# LPC18xx register map
File version: 18
Registers are 32-bit, read-write, reset 0x0 unless marked. A register's access mark holds for its fields unless they carry their own. Offsets are from the block's base; [hi:lo] are bit positions; 'fields as' and 'values as' point back to an identical list.

## RTC — Product name title=UM10430 Chapter title=LPC18xx Real-Time Clock (RTC) Modification date=1/20/2011 Major revision=0 Minor revision=7
Base 0x40046000
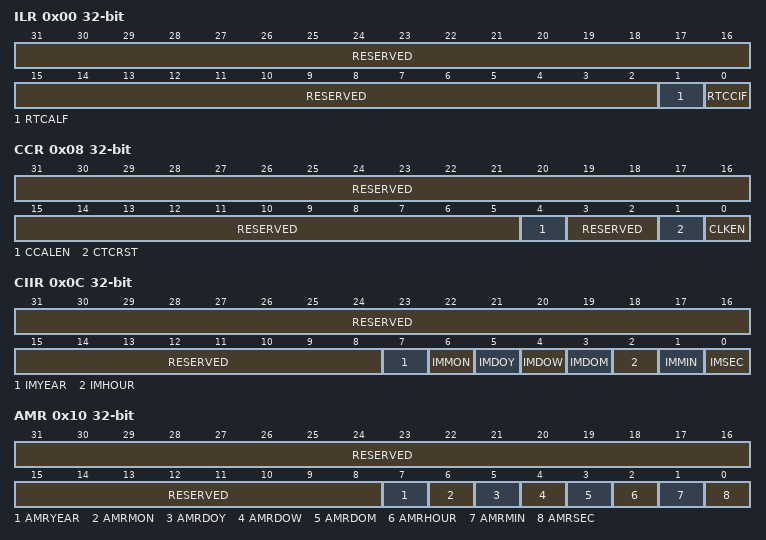
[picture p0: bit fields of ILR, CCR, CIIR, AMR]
0x00 ILR wo — Interrupt Location Register
  [31:2] RESERVED — Reserved, user software should not write ones to reserved bits. The value read from a reserved bit is not defined.
  [1] RTCALF — When one, the alarm registers generated an interrupt. Writing a one to this bit location clears the alarm interrupt.
  [0] RTCCIF — When one, the Counter Increment Interrupt block generated an interrupt. Writing a one to this bit location clears the counter increment interrupt.
0x08 CCR — Clock Control Register
  [31:5] RESERVED — Reserved, user software should not write ones to reserved bits. The value read from a reserved bit is not defined.
  [4] CCALEN — Calibration counter enable.
    0=ENABLED (The calibration counter is enabled and counting, using the 1 Hz clock. When the calibration counter is equal to the value of the CALIBRATION register, the counter resets and repeats counting up to the value of the CALIBRATION register. See Section 29.6.6.2 and Section 29.7.1.); 1=DISABLED (The calibration counter is disabled and reset to zero.)
  [3:2] RESERVED — Internal test mode controls. These bits must be 0 for normal RTC operation.
  [1] CTCRST — CTC Reset.
    0=NO_EFFECT_; 1=Reset value (When one, the elements in the internal oscillator divider are reset, and remain reset until CCR[1] is changed to zero. This is the divider that generates the 1 Hz clock from the 32.768 kHz crystal. The state of the divider is not visible to software.)
  [0] CLKEN — Clock Enable.
    0=DISABLED (The time counters are disabled so that they may be initialized.); 1=ENABLED (The time counters are enabled.)
0x0C CIIR — Counter Increment Interrupt Register
  [31:8] RESERVED — Reserved, user software should not write ones to reserved bits. The value read from a reserved bit is not defined.
  [7] IMYEAR — When 1, an increment of the Year value generates an interrupt.
  [6] IMMON — When 1, an increment of the Month value generates an interrupt.
  [5] IMDOY — When 1, an increment of the Day of Year value generates an interrupt.
  [4] IMDOW — When 1, an increment of the Day of Week value generates an interrupt.
  [3] IMDOM — When 1, an increment of the Day of Month value generates an interrupt.
  [2] IMHOUR — When 1, an increment of the Hour value generates an interrupt.
  [1] IMMIN — When 1, an increment of the Minute value generates an interrupt.
  [0] IMSEC — When 1, an increment of the Second value generates an interrupt.
0x10 AMR — Alarm Mask Register
  [31:8] RESERVED — Reserved, user software should not write ones to reserved bits. The value read from a reserved bit is not defined.
  [7] AMRYEAR — When 1, the Year value is not compared for the alarm.
  [6] AMRMON — When 1, the Month value is not compared for the alarm.
  [5] AMRDOY — When 1, the Day of Year value is not compared for the alarm.
  [4] AMRDOW — When 1, the Day of Week value is not compared for the alarm.
  [3] AMRDOM — When 1, the Day of Month value is not compared for the alarm.
  [2] AMRHOUR — When 1, the Hour value is not compared for the alarm.
  [1] AMRMIN — When 1, the Minutes value is not compared for the alarm.
  [0] AMRSEC — When 1, the Second value is not compared for the alarm.
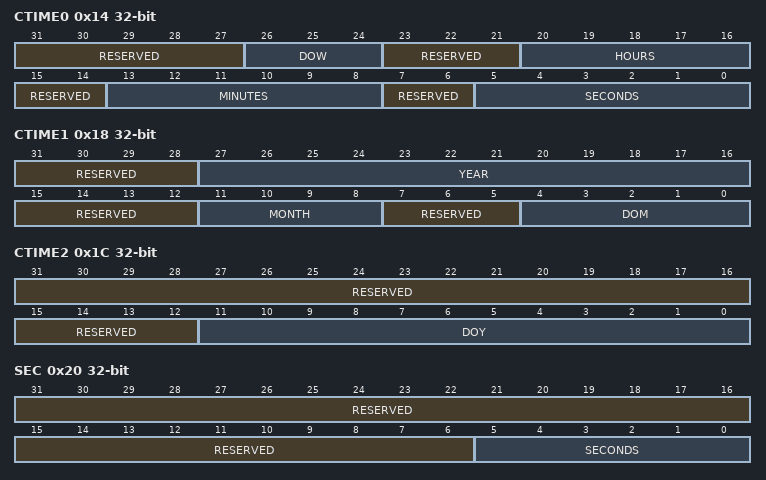
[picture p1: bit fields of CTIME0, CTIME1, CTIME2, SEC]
0x14 CTIME0 ro — Consolidated Time Register 0
  [31:27] RESERVED — Reserved, user software should not write ones to reserved bits. The value read from a reserved bit is not defined.
  [26:24] DOW — Day of week value in the range of 0 to 6
  [23:21] RESERVED — Reserved, user software should not write ones to reserved bits. The value read from a reserved bit is not defined.
  [20:16] HOURS — Hours value in the range of 0 to 23
  [15:14] RESERVED — Reserved, user software should not write ones to reserved bits. The value read from a reserved bit is not defined.
  [13:8] MINUTES — Minutes value in the range of 0 to 59
  [7:6] RESERVED — Reserved, user software should not write ones to reserved bits. The value read from a reserved bit is not defined.
  [5:0] SECONDS — Seconds value in the range of 0 to 59
0x18 CTIME1 ro — Consolidated Time Register 1
  [31:28] RESERVED — Reserved, user software should not write ones to reserved bits. The value read from a reserved bit is not defined.
  [27:16] YEAR — Year value in the range of 0 to 4095.
  [15:12] RESERVED — Reserved, user software should not write ones to reserved bits. The value read from a reserved bit is not defined.
  [11:8] MONTH — Month value in the range of 1 to 12.
  [7:5] RESERVED — Reserved, user software should not write ones to reserved bits. The value read from a reserved bit is not defined.
  [4:0] DOM — Day of month value in the range of 1 to 28, 29, 30, or 31 (depending on the month and whether it is a leap year).
0x1C CTIME2 ro — Consolidated Time Register 2
  [31:12] RESERVED — Reserved, user software should not write ones to reserved bits. The value read from a reserved bit is not defined.
  [11:0] DOY — Day of year value in the range of 1 to 365 (366 for leap years).
0x20 SEC — Seconds Register
  [31:6] RESERVED — Reserved, user software should not write ones to reserved bits. The value read from a reserved bit is not defined.
  [5:0] SECONDS — Seconds value in the range of 0 to 59
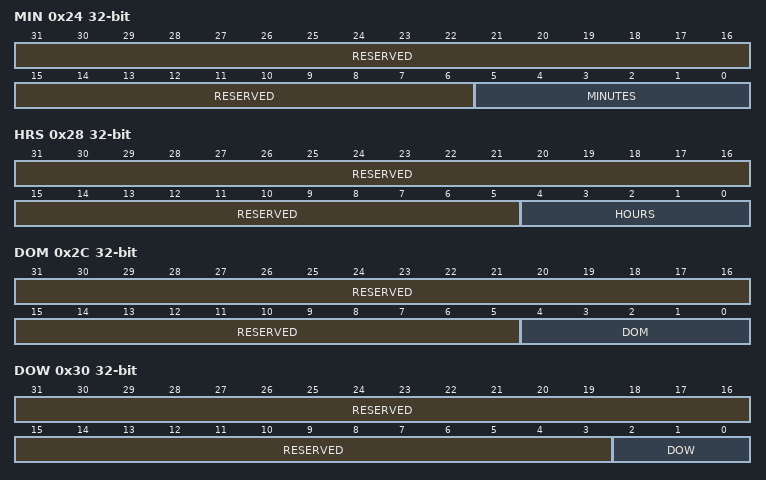
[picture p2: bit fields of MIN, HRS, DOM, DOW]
0x24 MIN — Minutes Register
  [31:6] RESERVED — Reserved, user software should not write ones to reserved bits. The value read from a reserved bit is not defined.
  [5:0] MINUTES — Minutes value in the range of 0 to 59
0x28 HRS — Hours Register
  [31:5] RESERVED — Reserved, user software should not write ones to reserved bits. The value read from a reserved bit is not defined.
  [4:0] HOURS — Hours value in the range of 0 to 23
0x2C DOM — Day of Month Register
  [31:5] RESERVED — Reserved, user software should not write ones to reserved bits. The value read from a reserved bit is not defined.
  [4:0] DOM — Day of month value in the range of 1 to 28, 29, 30, or 31 (depending on the month and whether it is a leap year).
0x30 DOW — Day of Week Register
  [31:3] RESERVED — Reserved, user software should not write ones to reserved bits. The value read from a reserved bit is not defined.
  [2:0] DOW — Day of week value in the range of 0 to 6.
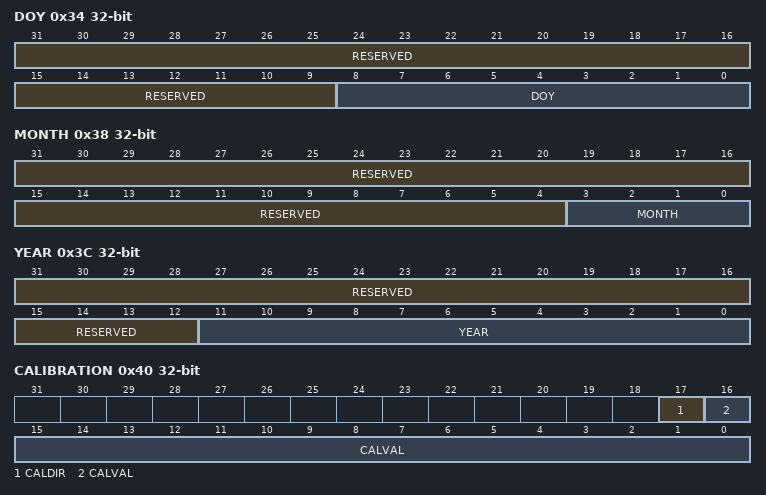
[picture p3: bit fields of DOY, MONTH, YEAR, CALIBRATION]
0x34 DOY — Day of Year Register
  [31:9] RESERVED — Reserved, user software should not write ones to reserved bits. The value read from a reserved bit is not defined.
  [8:0] DOY — Day of year value in the range of 1 to 365 (366 for leap years).
0x38 MONTH — Months Register
  [31:4] RESERVED — Reserved, user software should not write ones to reserved bits. The value read from a reserved bit is not defined.
  [3:0] MONTH — Month value in the range of 1 to 12.
0x3C YEAR — Years Register
  [31:12] RESERVED — Reserved, user software should not write ones to reserved bits. The value read from a reserved bit is not defined.
  [11:0] YEAR — Year value in the range of 0 to 4095.
0x40 CALIBRATION — Calibration Value Register
  [17] CALDIR — Calibration direction
    0=FORWARD_CALIBRATION_ (Forward calibration. When CALVAL is equal to the calibration counter, the RTC timers will jump by 2 seconds.); 1=BACKWARD_CALIBRATION (Backward calibration. When CALVAL is equal to the calibration counter, the RTC timers will stop incrementing for 1 second.)
  [16:0] CALVAL — If enabled, the calibration counter counts up to this value. The maximum value is 131 072 corresponding to about 36.4 hours. Calibration is disabled if CALVAL = 0.
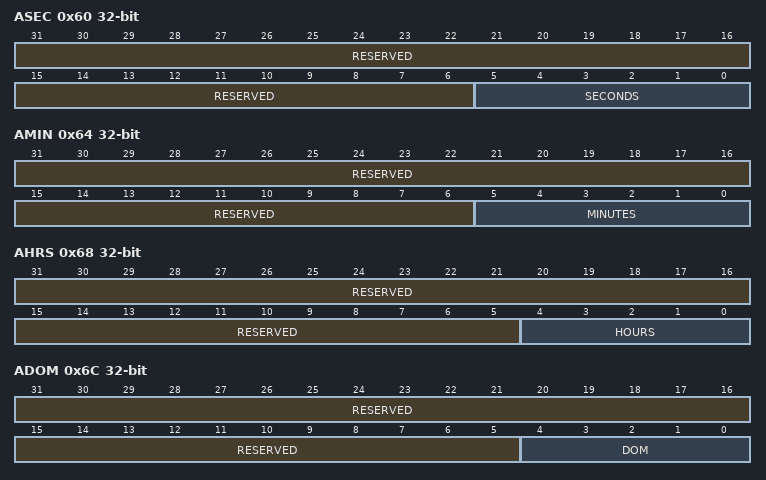
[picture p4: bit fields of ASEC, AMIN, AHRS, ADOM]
0x60 ASEC — Alarm value for Seconds
  fields as SEC
0x64 AMIN — Alarm value for Minutes
  fields as MIN
0x68 AHRS — Alarm value for Hours
  fields as HRS
0x6C ADOM — Alarm value for Day of Month
  fields as DOM
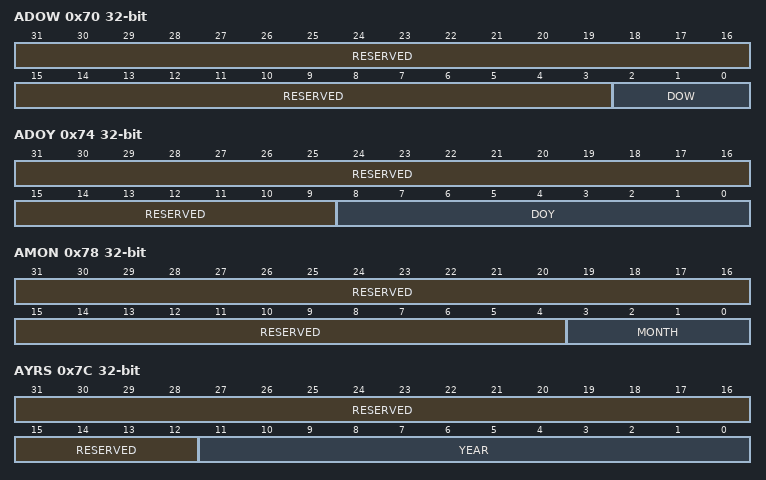
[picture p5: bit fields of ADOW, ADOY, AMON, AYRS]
0x70 ADOW — Alarm value for Day of Week
  fields as DOW
0x74 ADOY — Alarm value for Day of Year
  fields as DOY
0x78 AMON — Alarm value for Months
  fields as MONTH
0x7C AYRS — Alarm value for Year
  fields as YEAR
